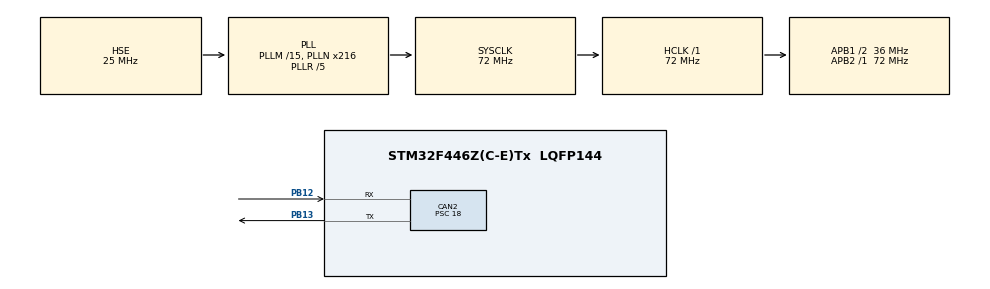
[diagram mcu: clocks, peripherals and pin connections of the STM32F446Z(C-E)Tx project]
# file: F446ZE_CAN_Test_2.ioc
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CAN2.BS1=CAN_BS1_2TQ
CAN2.CalculateBaudRate=500000
CAN2.CalculateTimeBit=2000.00
CAN2.CalculateTimeQuantum=500.0
CAN2.Mode=CAN_MODE_LOOPBACK
CAN2.Prescaler=18
Mcu.Family=STM32F4
Mcu.Name=STM32F446Z(C-E)Tx
Mcu.Package=LQFP144
NVIC.CAN2_RX0_IRQn=true\:0\:0\:false\:false\:true\:true\:true
NVIC.CAN2_RX1_IRQn=true\:0\:0\:false\:false\:true\:true\:true
NVIC.PriorityGroup=NVIC_PRIORITYGROUP_4
PA13.Mode=Serial_Wire
PA13.Signal=SYS_JTMS-SWDIO
PA14.Mode=Serial_Wire
PA14.Signal=SYS_JTCK-SWCLK
PB12.Mode=CAN_Activate
PB12.Signal=CAN2_RX
PB13.Mode=CAN_Activate
PB13.Signal=CAN2_TX
PH0-OSC_IN.Mode=HSE-External-Oscillator
PH0-OSC_IN.Signal=RCC_OSC_IN
PH1-OSC_OUT.Mode=HSE-External-Oscillator
PH1-OSC_OUT.Signal=RCC_OSC_OUT
ProjectManager.HeapSize=0x200
ProjectManager.StackSize=0x400
ProjectManager.TargetToolchain=STM32CubeIDE
RCC.AHBFreq_Value=72000000
RCC.APB1CLKDivider=RCC_HCLK_DIV2
RCC.APB1Freq_Value=36000000
RCC.APB1TimFreq_Value=72000000
RCC.APB2Freq_Value=72000000
RCC.APB2TimFreq_Value=72000000
RCC.CortexFreq_Value=72000000
RCC.HCLKFreq_Value=72000000
RCC.PLLM=15
RCC.PLLN=216
RCC.PLLR=5
RCC.PLLSourceVirtual=RCC_PLLSOURCE_HSE
RCC.SYSCLKFreq_VALUE=72000000
RCC.SYSCLKSource=RCC_SYSCLKSOURCE_PLLRCLK
RCC.USBFreq_Value=180000000
RCC.VCOOutputFreq_Value=360000000
board=custom

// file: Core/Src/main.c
/* USER CODE BEGIN Header */
/**
  ******************************************************************************
  * @file           : main.c
  * @brief          : Main program body
  ******************************************************************************
  * @attention
  *
  * <h2><center>&copy; Copyright (c) 2022 STMicroelectronics.
  * All rights reserved.</center></h2>
  *
  * This software component is licensed by ST under BSD 3-Clause license,
  * the "License"; You may not use this file except in compliance with the
  * License. You may obtain a copy of the License at:
  *                        opensource.org/licenses/BSD-3-Clause
  *
  ******************************************************************************
  */
/* USER CODE END Header */
#include "main.h"

CAN_HandleTypeDef hcan2;

void SystemClock_Config(void);
static void MX_GPIO_Init(void);
static void MX_CAN2_Init(void);

/* USER CODE BEGIN 0 */
CAN_TxHeaderTypeDef TxHeader; //tx header
CAN_RxHeaderTypeDef RxHeader; //rx header

uint32_t canMailbox; //mailbox holder

uint8_t TxData[8];  //tx bufer
uint8_t RxData[8];  //rx buffer

uint8_t count = 0;

void HAL_CAN_RxFifo0MsgPendingCallback(CAN_HandleTypeDef *hcan)
{
	count++;
//	HAL_CAN_GetRxMessage(hcan, CAN_RX_FIFO0, &RxHeader, RxData);
//	HAL_GPIO_TogglePin(LD1_GPIO_Port, LD1_Pin);
}

/* USER CODE END 0 */

int main(void)
{

  /* MCU Configuration--------------------------------------------------------*/

  /* Reset of all peripherals, Initializes the Flash interface and the Systick. */
  HAL_Init();

  /* Configure the system clock */
  SystemClock_Config();

  /* Initialize all configured peripherals */
  MX_GPIO_Init();
  MX_CAN2_Init();
  /* USER CODE BEGIN 2 */

  //start can peripheral
  HAL_CAN_Start(&hcan2);

  //inilitlize callback function
  HAL_CAN_ActivateNotification(&hcan2, CAN_IT_RX_FIFO0_MSG_PENDING);

  TxHeader.DLC = 1; //message size of two bytes
  TxHeader.ExtId = 0;
  TxHeader.IDE = CAN_ID_STD; //use standard ID formats
  TxHeader.RTR = CAN_RTR_DATA; //data type for transmit frame
  TxHeader.StdId = 0x103; //ID of the transmitter
  TxHeader.TransmitGlobalTime = DISABLE;

  TxData[0] = 0xf3;

  HAL_CAN_AddTxMessage(&hcan2, &TxHeader, TxData, &canMailbox);

  /* USER CODE END 2 */

  /* Infinite loop */
  while (1)
  {

  }
}

void SystemClock_Config(void)
{
  RCC_OscInitTypeDef RCC_OscInitStruct = {0};
  RCC_ClkInitTypeDef RCC_ClkInitStruct = {0};

  /** Configure the main internal regulator output voltage
  */
  __HAL_RCC_PWR_CLK_ENABLE();
  __HAL_PWR_VOLTAGESCALING_CONFIG(PWR_REGULATOR_VOLTAGE_SCALE3);
  /** Initializes the RCC Oscillators according to the specified parameters
  * in the RCC_OscInitTypeDef structure.
  */
  RCC_OscInitStruct.OscillatorType = RCC_OSCILLATORTYPE_HSE;
  RCC_OscInitStruct.HSEState = RCC_HSE_ON;
  RCC_OscInitStruct.PLL.PLLState = RCC_PLL_ON;
  RCC_OscInitStruct.PLL.PLLSource = RCC_PLLSOURCE_HSE;
  RCC_OscInitStruct.PLL.PLLM = 15;
  RCC_OscInitStruct.PLL.PLLN = 216;
  RCC_OscInitStruct.PLL.PLLP = RCC_PLLP_DIV2;
  RCC_OscInitStruct.PLL.PLLQ = 2;
  RCC_OscInitStruct.PLL.PLLR = 5;
  if (HAL_RCC_OscConfig(&RCC_OscInitStruct) != HAL_OK)
  {
    Error_Handler();
  }
  /** Initializes the CPU, AHB and APB buses clocks
  */
  RCC_ClkInitStruct.ClockType = RCC_CLOCKTYPE_HCLK|RCC_CLOCKTYPE_SYSCLK
                              |RCC_CLOCKTYPE_PCLK1|RCC_CLOCKTYPE_PCLK2;
  RCC_ClkInitStruct.SYSCLKSource = RCC_SYSCLKSOURCE_PLLRCLK;
  RCC_ClkInitStruct.AHBCLKDivider = RCC_SYSCLK_DIV1;
  RCC_ClkInitStruct.APB1CLKDivider = RCC_HCLK_DIV2;
  RCC_ClkInitStruct.APB2CLKDivider = RCC_HCLK_DIV1;

  if (HAL_RCC_ClockConfig(&RCC_ClkInitStruct, FLASH_LATENCY_2) != HAL_OK)
  {
    Error_Handler();
  }
}

static void MX_CAN2_Init(void)
{

  hcan2.Instance = CAN2;
  hcan2.Init.Prescaler = 18;
  hcan2.Init.Mode = CAN_MODE_LOOPBACK;
  hcan2.Init.SyncJumpWidth = CAN_SJW_1TQ;
  hcan2.Init.TimeSeg1 = CAN_BS1_2TQ;
  hcan2.Init.TimeSeg2 = CAN_BS2_1TQ;
  hcan2.Init.TimeTriggeredMode = DISABLE;
  hcan2.Init.AutoBusOff = DISABLE;
  hcan2.Init.AutoWakeUp = DISABLE;
  hcan2.Init.AutoRetransmission = DISABLE;
  hcan2.Init.ReceiveFifoLocked = DISABLE;
  hcan2.Init.TransmitFifoPriority = DISABLE;
  if (HAL_CAN_Init(&hcan2) != HAL_OK)
  {
    Error_Handler();
  }
  /* USER CODE BEGIN CAN2_Init 2 */
  CAN_FilterTypeDef canFilterConfig;  //can filter config
    canFilterConfig.FilterActivation = CAN_FILTER_ENABLE;
    canFilterConfig.FilterBank = 10;
    canFilterConfig.FilterFIFOAssignment = CAN_FILTER_FIFO0;
    canFilterConfig.FilterIdHigh = 0;
    canFilterConfig.FilterIdLow = 0x00000;
    canFilterConfig.FilterMaskIdHigh = 0;
    canFilterConfig.FilterMaskIdLow = 0x0000;
    canFilterConfig.FilterMode = CAN_FILTERMODE_IDMASK;
    canFilterConfig.FilterScale = CAN_FILTERSCALE_32BIT;
    canFilterConfig.SlaveStartFilterBank = 0;
    //Configuring CAN filter for CAN1
    HAL_CAN_ConfigFilter(&hcan2, &canFilterConfig);
  /* USER CODE END CAN2_Init 2 */

}

static void MX_GPIO_Init(void)
{

  /* GPIO Ports Clock Enable */
  __HAL_RCC_GPIOH_CLK_ENABLE();
  __HAL_RCC_GPIOB_CLK_ENABLE();
  __HAL_RCC_GPIOA_CLK_ENABLE();

}

void Error_Handler(void)
{
  __disable_irq();
  while (1)
  {
  }
}

/************************ (C) COPYRIGHT STMicroelectronics *****END OF FILE****/
